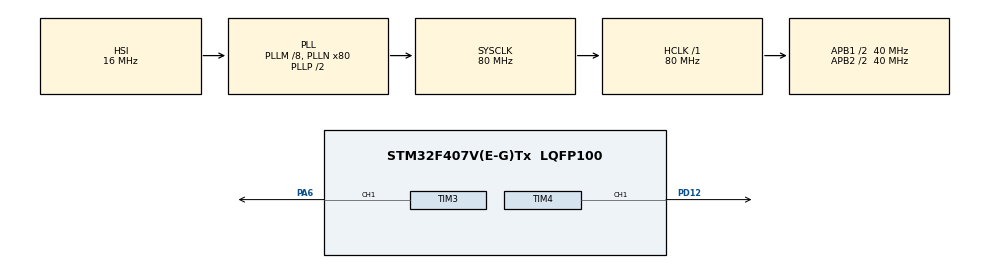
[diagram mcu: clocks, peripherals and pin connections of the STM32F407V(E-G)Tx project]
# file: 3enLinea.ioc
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Dma.Request0=TIM4_CH1
Dma.TIM4_CH1.0.Direction=DMA_MEMORY_TO_PERIPH
Dma.TIM4_CH1.0.FIFOMode=DMA_FIFOMODE_DISABLE
Dma.TIM4_CH1.0.Instance=DMA1_Stream0
Dma.TIM4_CH1.0.MemDataAlignment=DMA_MDATAALIGN_HALFWORD
Dma.TIM4_CH1.0.MemInc=DMA_MINC_ENABLE
Dma.TIM4_CH1.0.Mode=DMA_NORMAL
Dma.TIM4_CH1.0.PeriphDataAlignment=DMA_PDATAALIGN_HALFWORD
Dma.TIM4_CH1.0.PeriphInc=DMA_PINC_DISABLE
Dma.TIM4_CH1.0.Priority=DMA_PRIORITY_LOW
Mcu.Family=STM32F4
Mcu.Name=STM32F407V(E-G)Tx
Mcu.Package=LQFP100
NVIC.DMA1_Stream0_IRQn=true\:0\:0\:false\:false\:true\:false\:true\:true
NVIC.PriorityGroup=NVIC_PRIORITYGROUP_0
NVIC.RCC_IRQn=true\:0\:0\:false\:false\:true\:true\:false\:true
PA6.Signal=S_TIM3_CH1
PD12.Signal=S_TIM4_CH1
ProjectManager.HeapSize=0x200
ProjectManager.StackSize=0x400
ProjectManager.TargetToolchain=STM32CubeIDE
RCC.48MHZClocksFreq_Value=22857142.85714286
RCC.AHBFreq_Value=80000000
RCC.APB1CLKDivider=RCC_HCLK_DIV2
RCC.APB1Freq_Value=40000000
RCC.APB1TimFreq_Value=80000000
RCC.APB2CLKDivider=RCC_HCLK_DIV2
RCC.APB2Freq_Value=40000000
RCC.APB2TimFreq_Value=80000000
RCC.CortexFreq_Value=80000000
RCC.HCLKFreq_Value=80000000
RCC.HSE_VALUE=8000000
RCC.HSI_VALUE=16000000
RCC.LSE_VALUE=32768
RCC.PLLM=8
RCC.PLLN=80
RCC.PLLQ=7
RCC.SYSCLKFreq_VALUE=80000000
RCC.SYSCLKSource=RCC_SYSCLKSOURCE_PLLCLK
RCC.VCOOutputFreq_Value=160000000
SH.S_TIM3_CH1.0=TIM3_CH1,PWM Generation1 CH1
SH.S_TIM4_CH1.0=TIM4_CH1,PWM Generation1 CH1
TIM3.Channel-PWM\ Generation1\ CH1=TIM_CHANNEL_1
TIM3.Period=3
TIM3.Prescaler=9999
TIM4.AutoReloadPreload=TIM_AUTORELOAD_PRELOAD_ENABLE
TIM4.Channel-PWM\ Generation1\ CH1=TIM_CHANNEL_1
TIM4.Period=49
TIM4.Prescaler=1
VP_TIM3_VS_ClockSourceINT.Mode=Internal
VP_TIM4_VS_ClockSourceINT.Mode=Internal
board=STM32F407G-DISC1

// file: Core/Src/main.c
/* USER CODE BEGIN Header */
/**
  ******************************************************************************
  * @file           : main.c
  * @brief          : Main program body
  ******************************************************************************
  * @attention
  *
  * Copyright (c) 2026 STMicroelectronics.
  * All rights reserved.
  *
  * This software is licensed under terms that can be found in the LICENSE file
  * in the root directory of this software component.
  * If no LICENSE file comes with this software, it is provided AS-IS.
  *
  ******************************************************************************
  */
/* USER CODE END Header */
#include "main.h"

/* USER CODE BEGIN Includes */
#include "LEDS.h"
#include "MEMORIA.h"
#include "Buzzer.h"
/* USER CODE END Includes */

/* USER CODE BEGIN PD */
#define tamaño 32
#define TENCENDIDO 200
/* USER CODE END PD */

TIM_HandleTypeDef htim3;
TIM_HandleTypeDef htim4;
DMA_HandleTypeDef hdma_tim4_ch1;

/* USER CODE BEGIN PV */

uint32_t D1  = 0x000001;
uint32_t D2  = 0x000001;
uint32_t D3  = 0x000001;
uint32_t D4  = 0x000001;
uint32_t D5  = 0x000001;
uint32_t D6  = 0x000001;

uint32_t D7  = 0x000001;
uint32_t D8  = 0x000001;
uint32_t D9  = 0x000001;
uint32_t D10 = 0x000001;
uint32_t D11 = 0x000001;
uint32_t D12 = 0x000001;

uint32_t D13 = 0x000001;
uint32_t D14 = 0x000000;
uint32_t D15 = 0x000001;
uint32_t D16 = 0x000001;
uint32_t D17 = 0x000001;
uint32_t D18 = 0x000101;

uint32_t D19 = 0x000100;
uint32_t D20 = 0x000100;
uint32_t D21 = 0x000100;
uint32_t D22 = 0x000100;

uint32_t D23 = 0x000100;
uint32_t D24 = 0x000100;
uint32_t D25 = 0x000100;
uint32_t D26 = 0x000100;

uint32_t D27 = 0x000100;
uint32_t D28 = 0x000100;
uint32_t D29 = 0x000100;
uint32_t D30 = 0x010000;

uint32_t D31 = 0x000100;
uint32_t D32 = 0x000100;
uint32_t L[32] = {0};
uint32_t vectorled[818] = {0};
char M[8][4] = {0};
char Teclado_Accionado = 0;
char ganaj1 = 0;
char ganaj2 = 0;
char jugada = 0;
/* USER CODE END PV */

void SystemClock_Config(void);
static void MX_GPIO_Init(void);
static void MX_DMA_Init(void);
static void MX_TIM4_Init(void);
static void MX_TIM3_Init(void);
/* USER CODE BEGIN PFP */
void inicio(void);
/* USER CODE END PFP */

int main(void)
{

  /* MCU Configuration--------------------------------------------------------*/

  /* Reset of all peripherals, Initializes the Flash interface and the Systick. */
  HAL_Init();

  /* Configure the system clock */
  SystemClock_Config();

  /* Initialize all configured peripherals */
  MX_GPIO_Init();
  MX_DMA_Init();
  MX_TIM4_Init();
  MX_TIM3_Init();
  /* USER CODE BEGIN 2 */
  	  	HAL_TIM_PWM_Start(&htim3, TIM_CHANNEL_1);
  	  	TIM4->CCR1 = 0;
  	    buzz();
    	inicio();
    	L[0]  = D1;
    	  	    L[1]  = D2;
    	  	    L[2]  = D3;
    	  	    L[3]  = D4;
    	  	    L[4]  = D5;
    	  	    L[5]  = D6;
    	  	    L[6]  = D7;
    	  	    L[7]  = D8;
    	  	    L[8]  = D9;
    	  	    L[9]  = D10;
    	  	    L[10] = D11;
    	  	    L[11] = D12;
    	  	    L[12] = D13;
    	  	    L[13] = D14;
    	  	    L[14] = D15;
    	  	    L[15] = D16;
    	  	    L[16] = D17;
    	  	    L[17] = D18;
    	  	    L[18] = D19;
    	  	    L[19] = D20;
    	  	    L[20] = D21;
    	  	    L[21] = D22;
    	  	    L[22] = D23;
    	  	    L[23] = D24;
    	  	    L[24] = D25;
    	  	    L[25] = D26;
    	  	    L[26] = D27;
    	  	    L[27] = D28;
    	  	    L[28] = D29;
    	  	    L[29] = D30;
    	  	    L[30] = D31;
    	  	    L[31] = D32;
    	  	  comunicacionled(L, vectorled);
    	  	ENVIODMA(vectorled);
  	    inicio();
  	    buzz();
  /* USER CODE END 2 */

  /* Infinite loop */
  while (1)
  {

  }
}

void SystemClock_Config(void)
{
  RCC_OscInitTypeDef RCC_OscInitStruct = {0};
  RCC_ClkInitTypeDef RCC_ClkInitStruct = {0};

  /** Configure the main internal regulator output voltage
  */
  __HAL_RCC_PWR_CLK_ENABLE();
  __HAL_PWR_VOLTAGESCALING_CONFIG(PWR_REGULATOR_VOLTAGE_SCALE1);

  /** Initializes the RCC Oscillators according to the specified parameters
  * in the RCC_OscInitTypeDef structure.
  */
  RCC_OscInitStruct.OscillatorType = RCC_OSCILLATORTYPE_HSI;
  RCC_OscInitStruct.HSIState = RCC_HSI_ON;
  RCC_OscInitStruct.HSICalibrationValue = RCC_HSICALIBRATION_DEFAULT;
  RCC_OscInitStruct.PLL.PLLState = RCC_PLL_ON;
  RCC_OscInitStruct.PLL.PLLSource = RCC_PLLSOURCE_HSI;
  RCC_OscInitStruct.PLL.PLLM = 8;
  RCC_OscInitStruct.PLL.PLLN = 80;
  RCC_OscInitStruct.PLL.PLLP = RCC_PLLP_DIV2;
  RCC_OscInitStruct.PLL.PLLQ = 7;
  if (HAL_RCC_OscConfig(&RCC_OscInitStruct) != HAL_OK)
  {
    Error_Handler();
  }

  /** Initializes the CPU, AHB and APB buses clocks
  */
  RCC_ClkInitStruct.ClockType = RCC_CLOCKTYPE_HCLK|RCC_CLOCKTYPE_SYSCLK
                              |RCC_CLOCKTYPE_PCLK1|RCC_CLOCKTYPE_PCLK2;
  RCC_ClkInitStruct.SYSCLKSource = RCC_SYSCLKSOURCE_PLLCLK;
  RCC_ClkInitStruct.AHBCLKDivider = RCC_SYSCLK_DIV1;
  RCC_ClkInitStruct.APB1CLKDivider = RCC_HCLK_DIV2;
  RCC_ClkInitStruct.APB2CLKDivider = RCC_HCLK_DIV2;

  if (HAL_RCC_ClockConfig(&RCC_ClkInitStruct, FLASH_LATENCY_2) != HAL_OK)
  {
    Error_Handler();
  }
}

static void MX_TIM3_Init(void)
{

  TIM_ClockConfigTypeDef sClockSourceConfig = {0};
  TIM_MasterConfigTypeDef sMasterConfig = {0};
  TIM_OC_InitTypeDef sConfigOC = {0};

  htim3.Instance = TIM3;
  htim3.Init.Prescaler = 9999;
  htim3.Init.CounterMode = TIM_COUNTERMODE_UP;
  htim3.Init.Period = 3;
  htim3.Init.ClockDivision = TIM_CLOCKDIVISION_DIV1;
  htim3.Init.AutoReloadPreload = TIM_AUTORELOAD_PRELOAD_DISABLE;
  if (HAL_TIM_Base_Init(&htim3) != HAL_OK)
  {
    Error_Handler();
  }
  sClockSourceConfig.ClockSource = TIM_CLOCKSOURCE_INTERNAL;
  if (HAL_TIM_ConfigClockSource(&htim3, &sClockSourceConfig) != HAL_OK)
  {
    Error_Handler();
  }
  if (HAL_TIM_PWM_Init(&htim3) != HAL_OK)
  {
    Error_Handler();
  }
  sMasterConfig.MasterOutputTrigger = TIM_TRGO_RESET;
  sMasterConfig.MasterSlaveMode = TIM_MASTERSLAVEMODE_DISABLE;
  if (HAL_TIMEx_MasterConfigSynchronization(&htim3, &sMasterConfig) != HAL_OK)
  {
    Error_Handler();
  }
  sConfigOC.OCMode = TIM_OCMODE_PWM1;
  sConfigOC.Pulse = 0;
  sConfigOC.OCPolarity = TIM_OCPOLARITY_HIGH;
  sConfigOC.OCFastMode = TIM_OCFAST_DISABLE;
  if (HAL_TIM_PWM_ConfigChannel(&htim3, &sConfigOC, TIM_CHANNEL_1) != HAL_OK)
  {
    Error_Handler();
  }
  HAL_TIM_MspPostInit(&htim3);

}

static void MX_TIM4_Init(void)
{

  TIM_ClockConfigTypeDef sClockSourceConfig = {0};
  TIM_MasterConfigTypeDef sMasterConfig = {0};
  TIM_OC_InitTypeDef sConfigOC = {0};

  htim4.Instance = TIM4;
  htim4.Init.Prescaler = 1;
  htim4.Init.CounterMode = TIM_COUNTERMODE_UP;
  htim4.Init.Period = 49;
  htim4.Init.ClockDivision = TIM_CLOCKDIVISION_DIV1;
  htim4.Init.AutoReloadPreload = TIM_AUTORELOAD_PRELOAD_ENABLE;
  if (HAL_TIM_Base_Init(&htim4) != HAL_OK)
  {
    Error_Handler();
  }
  sClockSourceConfig.ClockSource = TIM_CLOCKSOURCE_INTERNAL;
  if (HAL_TIM_ConfigClockSource(&htim4, &sClockSourceConfig) != HAL_OK)
  {
    Error_Handler();
  }
  if (HAL_TIM_PWM_Init(&htim4) != HAL_OK)
  {
    Error_Handler();
  }
  sMasterConfig.MasterOutputTrigger = TIM_TRGO_RESET;
  sMasterConfig.MasterSlaveMode = TIM_MASTERSLAVEMODE_DISABLE;
  if (HAL_TIMEx_MasterConfigSynchronization(&htim4, &sMasterConfig) != HAL_OK)
  {
    Error_Handler();
  }
  sConfigOC.OCMode = TIM_OCMODE_PWM1;
  sConfigOC.Pulse = 0;
  sConfigOC.OCPolarity = TIM_OCPOLARITY_HIGH;
  sConfigOC.OCFastMode = TIM_OCFAST_DISABLE;
  if (HAL_TIM_PWM_ConfigChannel(&htim4, &sConfigOC, TIM_CHANNEL_1) != HAL_OK)
  {
    Error_Handler();
  }
  HAL_TIM_MspPostInit(&htim4);

}

static void MX_DMA_Init(void)
{

  /* DMA controller clock enable */
  __HAL_RCC_DMA1_CLK_ENABLE();

  /* DMA interrupt init */
  /* DMA1_Stream0_IRQn interrupt configuration */
  HAL_NVIC_SetPriority(DMA1_Stream0_IRQn, 0, 0);
  HAL_NVIC_EnableIRQ(DMA1_Stream0_IRQn);

}

static void MX_GPIO_Init(void)
{

  /* GPIO Ports Clock Enable */
  __HAL_RCC_GPIOA_CLK_ENABLE();
  __HAL_RCC_GPIOD_CLK_ENABLE();

}

/* USER CODE BEGIN 4 */
void inicio(void){
 // Obtenemos el valor máximo de ciclo de trabajo de la configuración del hgardware
 uint16_t ciclomaximo = TIM3->ARR; // Valor máximo de ciclo de trabajo
 // Configuramos el PWM para que inicie con los LED encendidos
 TIM3->CCR1 = ciclomaximo; // LED verde al 100 %
 // Arrancamos el PWM

 // Mantenemos los LED encendidos por un tiempo
 HAL_Delay(TENCENDIDO); // Retardo de TENCENDIDO milisegundos
 // Apagamos los LED
 TIM3->CCR1 = 0;
 HAL_Delay(TENCENDIDO);
 // Mantenemos los LED apagados por un tiempo
 //Encendemos el LED rojo
}
/* USER CODE END 4 */

void Error_Handler(void)
{
  __disable_irq();
  while (1)
  {
  }
}
